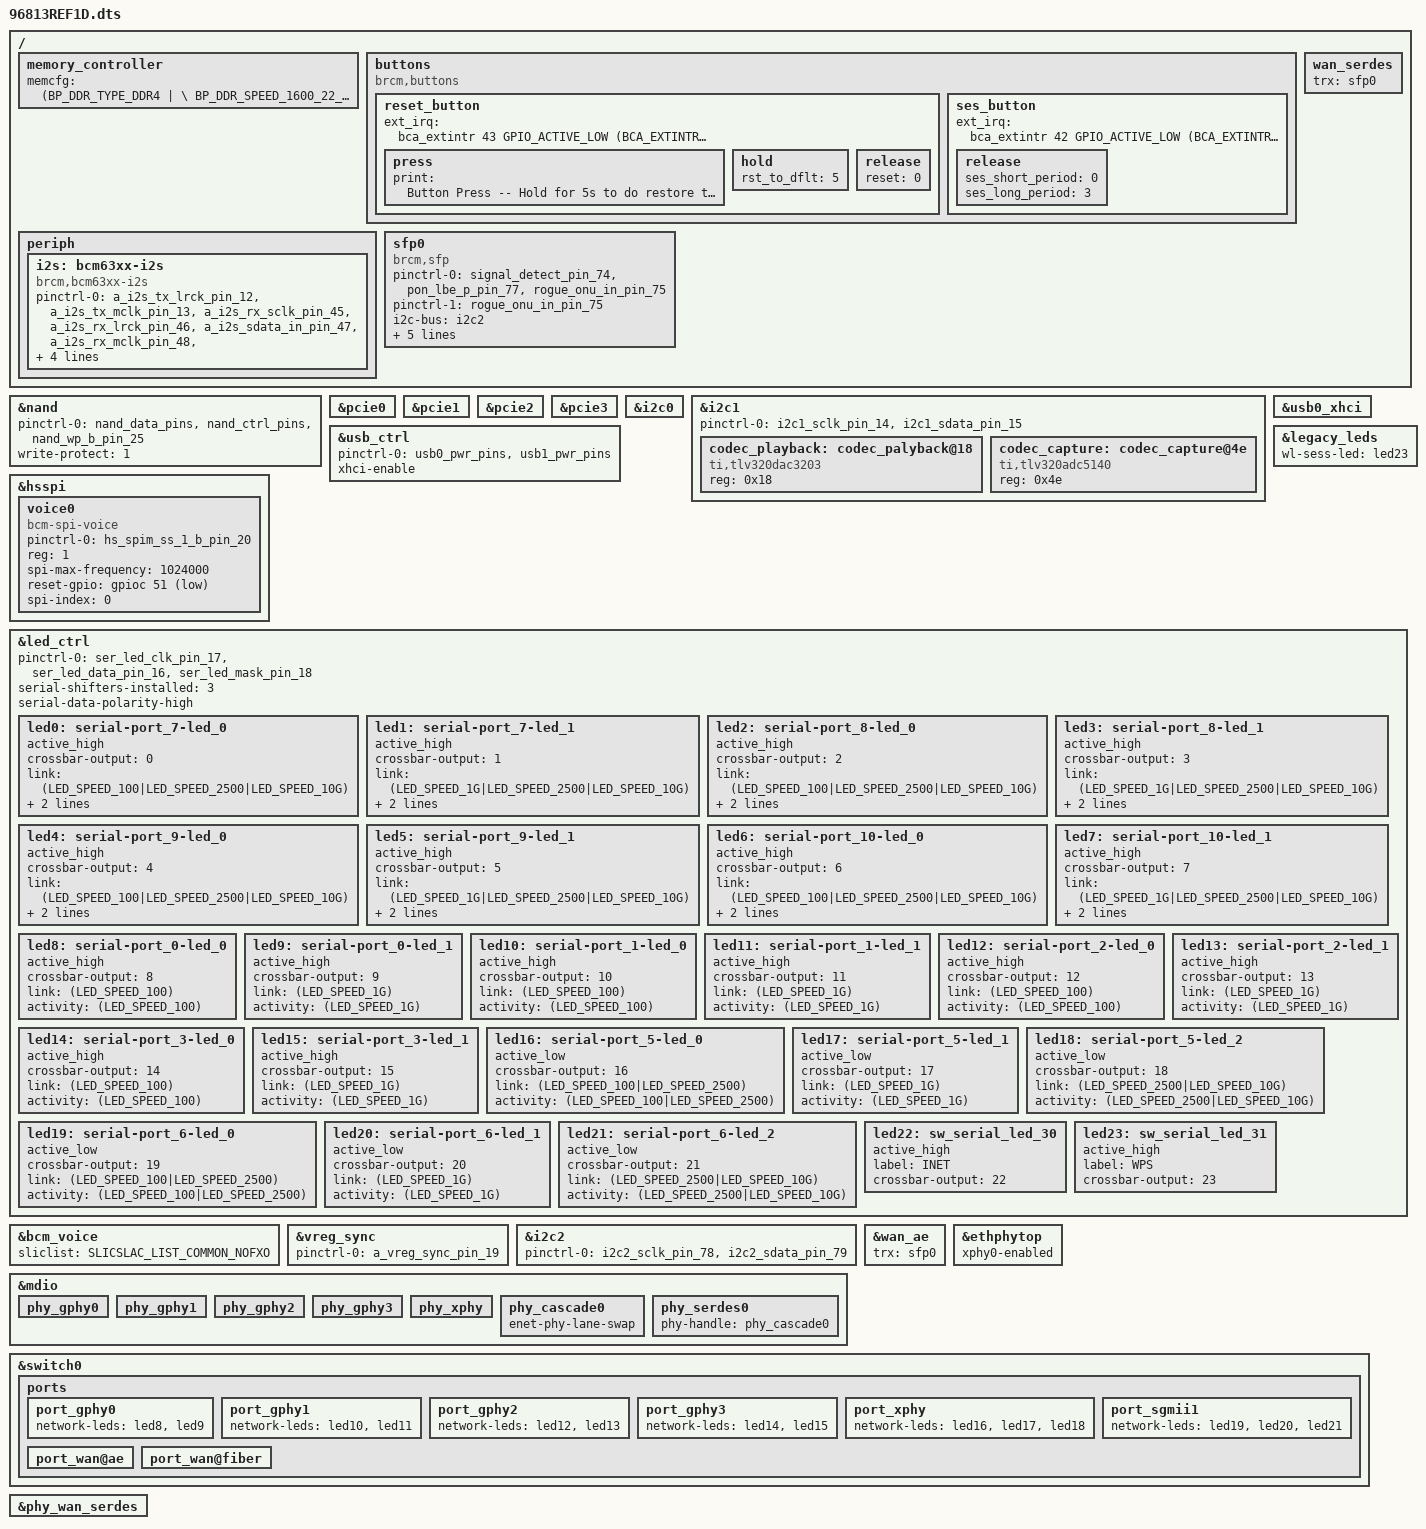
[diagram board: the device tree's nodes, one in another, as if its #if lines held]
#include "6813.dtsi"
#include "../bcm_voice.dtsi"

/ {
	memory_controller {
		memcfg = <(BP_DDR_TYPE_DDR4       | \
			BP_DDR_SPEED_1600_22_22_22    | \
			BP_DDR_TOTAL_SIZE_4096MB      | \
			BP_DDR_DEVICE_WIDTH_16        | \
			BP_DDR_TOTAL_WIDTH_32BIT      | \
			BP_DDR_6813_DEFAULT          | \
			BP_DDR_CONFIG_DEBUG)>;
	};

	buttons: buttons {
		compatible = "brcm,buttons";
		reset_button {
			ext_irq = <&bca_extintr 43 GPIO_ACTIVE_LOW (BCA_EXTINTR_TYPE_LOW_LEVEL | BCA_EXTINTR_TYPE_SENSE_EDGE)>;
			press {
				print = "Button Press -- Hold for 5s to do restore to default";
			};
			hold {
				rst_to_dflt = <5>;
			};
			release {
				reset = <0>;
			};
		};
		ses_button {
			ext_irq = <&bca_extintr 42 GPIO_ACTIVE_LOW (BCA_EXTINTR_TYPE_LOW_LEVEL | BCA_EXTINTR_TYPE_SENSE_EDGE)>;
			release {
				ses_short_period = <0>;
				ses_long_period = <3>;
			};
		};
	};

	periph {
		i2s: bcm63xx-i2s {
			pinctrl-0 = <&a_i2s_tx_lrck_pin_12 &a_i2s_tx_mclk_pin_13  &a_i2s_rx_sclk_pin_45 &a_i2s_rx_lrck_pin_46 &a_i2s_sdata_in_pin_47 &a_i2s_rx_mclk_pin_48 &a_i2s_sdata_out_pin_49 &a_i2s_tx_sclk_pin_50>;
			pinctrl-names = "default";
			compatible = "brcm,bcm63xx-i2s";
			reg = <0 0x2080 0 0x7f>;
			interrupts = <GIC_SPI 44 IRQ_TYPE_LEVEL_HIGH>;
			clocks = <&i2stxclk>,<&i2srxclk>,<&osc>;
			clock-names = "i2stxclk","i2srxclk","i2sosc";
		};
	};

	sfp0: sfp0 {
		/* REF1D board has gpio 71 connected to sig detect
		  Should be gpio 74. Must rework the board to make it work */
		compatible = "brcm,sfp";
		pinctrl-names = "default", "tx-sd";
		pinctrl-0 = <&signal_detect_pin_74 &pon_lbe_p_pin_77 &rogue_onu_in_pin_75>;
		pinctrl-1 = <&rogue_onu_in_pin_75>;
		
		i2c-bus = <&i2c2>;
		mod-def0 = <&bca_extintr 72 GPIO_ACTIVE_LOW (BCA_EXTINTR_TYPE_BOTH_EDGE | BCA_EXTINTR_TYPE_SENSE_EDGE)>;
		tx-power-gpio = <&gpioc 76 GPIO_ACTIVE_HIGH>;
		los-gpio = <&gpioc 74 GPIO_ACTIVE_HIGH>;
		tx-power-down-gpio = <&gpioc 71 GPIO_ACTIVE_HIGH>;				
	};

	wan_serdes {
		status = "okay";
		trx = <&sfp0>;
	};
};

&nand {
	pinctrl-0 = <&nand_data_pins &nand_ctrl_pins &nand_wp_b_pin_25>;
	write-protect = <1>;
	status = "okay";
};

#if defined(CONFIG_BCM_PCIE_HCD) || defined(CONFIG_BCM_PCIE_HCD_MODULE)
&pcie0 {
	status = "okay";
};
&pcie1 {
	status = "okay";
};
&pcie2 {
	status = "okay";
};
&pcie3 {
	status = "okay";
};
#endif //#if defined(CONFIG_BCM_PCIE_HCD) || defined(CONFIG_BCM_PCIE_HCD_MODULE)

&i2c0 {
	status = "okay";
};
&i2c1 {
	pinctrl-names = "default";
	pinctrl-0 = <&i2c1_sclk_pin_14 &i2c1_sdata_pin_15>;
	status = "okay";
	#address-cells = <1>;
	#size-cells = <0>;
	codec_playback:codec_palyback@18{
	compatible = "ti,tlv320dac3203";
	reg = <0x18>;
	};
	codec_capture:codec_capture@4e{
	compatible = "ti,tlv320adc5140";
	reg = <0x4e>;
	};
};

&usb_ctrl {
	pinctrl-names = "default";
	pinctrl-0 = <&usb0_pwr_pins &usb1_pwr_pins>;
	status = "okay";
	xhci-enable;
};
&usb0_xhci {
	status = "okay";
};

&hsspi {
	status = "okay";
	voice0 {
		pinctrl-0 = <&hs_spim_ss_1_b_pin_20>;
		pinctrl-names = "default";
		compatible = "bcm-spi-voice";
		reg = <1>; /* chip select 1 */
		spi-max-frequency = <1024000>;
		reset-gpio = <&gpioc 51 GPIO_ACTIVE_LOW>;
		spi-index = <0>;/* voice header index */
	};
};

&legacy_leds {
	wl-sess-led = <&led23>;
};

&led_ctrl {
	pinctrl-names = "default";
	pinctrl-0 = <&ser_led_clk_pin_17 &ser_led_data_pin_16 &ser_led_mask_pin_18>;
	serial-shifters-installed = <3>;
	serial-data-polarity-high;

	led0: serial-port_7-led_0 {
		active_high;
		crossbar-output = <0>;
		link = <(LED_SPEED_100|LED_SPEED_2500|LED_SPEED_10G)>;
		activity = <(LED_SPEED_100|LED_SPEED_2500|LED_SPEED_10G)>;
		status = "okay";
	};
	led1: serial-port_7-led_1 {
		active_high;
		crossbar-output = <1>;
		link = <(LED_SPEED_1G|LED_SPEED_2500|LED_SPEED_10G)>;
		activity = <(LED_SPEED_1G|LED_SPEED_2500|LED_SPEED_10G)>;
		status = "okay";
	};
	led2: serial-port_8-led_0 {
		active_high;
		crossbar-output = <2>;
		link = <(LED_SPEED_100|LED_SPEED_2500|LED_SPEED_10G)>;
		activity = <(LED_SPEED_100|LED_SPEED_2500|LED_SPEED_10G)>;
		status = "okay";
	};
	led3: serial-port_8-led_1 {
		active_high;
		crossbar-output = <3>;
		link = <(LED_SPEED_1G|LED_SPEED_2500|LED_SPEED_10G)>;
		activity = <(LED_SPEED_1G|LED_SPEED_2500|LED_SPEED_10G)>;
		status = "okay";
	};
	led4: serial-port_9-led_0 {
		active_high;
		crossbar-output = <4>;
		link = <(LED_SPEED_100|LED_SPEED_2500|LED_SPEED_10G)>;
		activity = <(LED_SPEED_100|LED_SPEED_2500|LED_SPEED_10G)>;
		status = "okay";
	};
	led5: serial-port_9-led_1 {
		active_high;
		crossbar-output = <5>;
		link = <(LED_SPEED_1G|LED_SPEED_2500|LED_SPEED_10G)>;
		activity = <(LED_SPEED_1G|LED_SPEED_2500|LED_SPEED_10G)>;
		status = "okay";
	};
	led6: serial-port_10-led_0 {
		active_high;
		crossbar-output = <6>;
		link = <(LED_SPEED_100|LED_SPEED_2500|LED_SPEED_10G)>;
		activity = <(LED_SPEED_100|LED_SPEED_2500|LED_SPEED_10G)>;
		status = "okay";
	};
	led7: serial-port_10-led_1 {
		active_high;
		crossbar-output = <7>;
		link = <(LED_SPEED_1G|LED_SPEED_2500|LED_SPEED_10G)>;
		activity = <(LED_SPEED_1G|LED_SPEED_2500|LED_SPEED_10G)>;
		status = "okay";
	};
	led8: serial-port_0-led_0 {
		active_high;
		crossbar-output = <8>;
		link = <(LED_SPEED_100)>;
		activity = <(LED_SPEED_100)>;
		status = "okay";
	};
	led9: serial-port_0-led_1 {
		active_high;
		crossbar-output = <9>;
		link = <(LED_SPEED_1G)>;
		activity = <(LED_SPEED_1G)>;
		status = "okay";
	};
	led10: serial-port_1-led_0 {
		active_high;
		crossbar-output = <10>;
		link = <(LED_SPEED_100)>;
		activity = <(LED_SPEED_100)>;
		status = "okay";
	};
	led11: serial-port_1-led_1 {
		active_high;
		crossbar-output = <11>;
		link = <(LED_SPEED_1G)>;
		activity = <(LED_SPEED_1G)>;
		status = "okay";
	};
	led12: serial-port_2-led_0 {
		active_high;
		crossbar-output = <12>;
		link = <(LED_SPEED_100)>;
		activity = <(LED_SPEED_100)>;
		status = "okay";
	};
	led13: serial-port_2-led_1 {
		active_high;
		crossbar-output = <13>;
		link = <(LED_SPEED_1G)>;
		activity = <(LED_SPEED_1G)>;
		status = "okay";
	};
	led14: serial-port_3-led_0 {
		active_high;
		crossbar-output = <14>;
		link = <(LED_SPEED_100)>;
		activity = <(LED_SPEED_100)>;
		status = "okay";
	};
	led15: serial-port_3-led_1 {
		active_high;
		crossbar-output = <15>;
		link = <(LED_SPEED_1G)>;
		activity = <(LED_SPEED_1G)>;
		status = "okay";
	};
	led16: serial-port_5-led_0 {
		active_low;
		crossbar-output = <16>;
		link = <(LED_SPEED_100|LED_SPEED_2500)>;
		activity = <(LED_SPEED_100|LED_SPEED_2500)>;
		status = "okay";
	};
	led17: serial-port_5-led_1 {
		active_low;
		crossbar-output = <17>;
		link = <(LED_SPEED_1G)>;
		activity = <(LED_SPEED_1G)>;
		status = "okay";
	};
	led18: serial-port_5-led_2 {
		active_low;
		crossbar-output = <18>;
		link = <(LED_SPEED_2500|LED_SPEED_10G)>;
		activity = <(LED_SPEED_2500|LED_SPEED_10G)>;
		status = "okay";
	};
	led19: serial-port_6-led_0 {
		active_low;
		crossbar-output = <19>;
		link = <(LED_SPEED_100|LED_SPEED_2500)>;
		activity = <(LED_SPEED_100|LED_SPEED_2500)>;
		status = "okay";
	};
	led20: serial-port_6-led_1 {
		active_low;
		crossbar-output = <20>;
		link = <(LED_SPEED_1G)>;
		activity = <(LED_SPEED_1G)>;
		status = "okay";
	};
	led21: serial-port_6-led_2 {
		active_low;
		crossbar-output = <21>;
		link = <(LED_SPEED_2500|LED_SPEED_10G)>;
		activity = <(LED_SPEED_2500|LED_SPEED_10G)>;
		status = "okay";
	};
	led22: sw_serial_led_30 {
		active_high;
		label = "INET";
		crossbar-output = <22>;
		status = "okay";
	};
	led23: sw_serial_led_31 {
		active_high;
		label = "WPS";
		crossbar-output = <23>;
		status = "okay";
	};

};
&bcm_voice{
	sliclist = SLICSLAC_LIST_COMMON_NOFXO;
 };

&vreg_sync {
		pinctrl-0 = <&a_vreg_sync_pin_19>;
		pinctrl-names = "default";
};

&i2c2 {
	pinctrl-names = "default";
	pinctrl-0 = <&i2c2_sclk_pin_78 &i2c2_sdata_pin_79>;
	status = "okay";
};

&mdio {
    /* Port PHY mapping:
            port_gphy0 <----> phy_gphy0
            port_gphy1 <----> phy_gphy1
            port_gphy2 <----> phy_gphy2
            port_gphy3 <----> phy_gphy3
            port_xphy <-----> phy_xphy
            port_sgmii1 <---> phy_serdes0   - phy_cascade0
     */
	phy_gphy0 {
		status = "okay";
	};

	phy_gphy1 {
		status = "okay";
	};

	phy_gphy2 {
		status = "okay";
	};

	phy_gphy3 {
		status = "okay";
	};

	phy_xphy {
		status = "okay";
	};

	phy_cascade0 {
	    enet-phy-lane-swap;
		status = "okay";
	};

	phy_serdes0 {
		phy-handle = <&phy_cascade0>;
		status = "okay";
	};

};

&wan_ae {
    status = "okay";
    trx = <&sfp0>;
};

&ethphytop {
    xphy0-enabled;
    status = "okay";
};

&switch0 {
	ports {
		port_gphy0 {
			network-leds = <&led8 &led9>;
			status = "okay";
		};

		port_gphy1 {
			network-leds = <&led10 &led11>;
			status = "okay";
		};

		port_gphy2 {
			network-leds = <&led12 &led13>;
			status = "okay";
		};

		port_gphy3 {
			network-leds = <&led14 &led15>;
			status = "okay";
		};

		port_xphy {
			network-leds = <&led16 &led17 &led18>;
			status = "okay";
		};

		port_sgmii1 {
			network-leds = <&led19 &led20 &led21>;
			status = "okay";
		};

		port_wan@ae {
			status = "okay";
		};

		port_wan@fiber {
			status = "okay";
		};
	};
};

&phy_wan_serdes {
	status = "okay";
};
